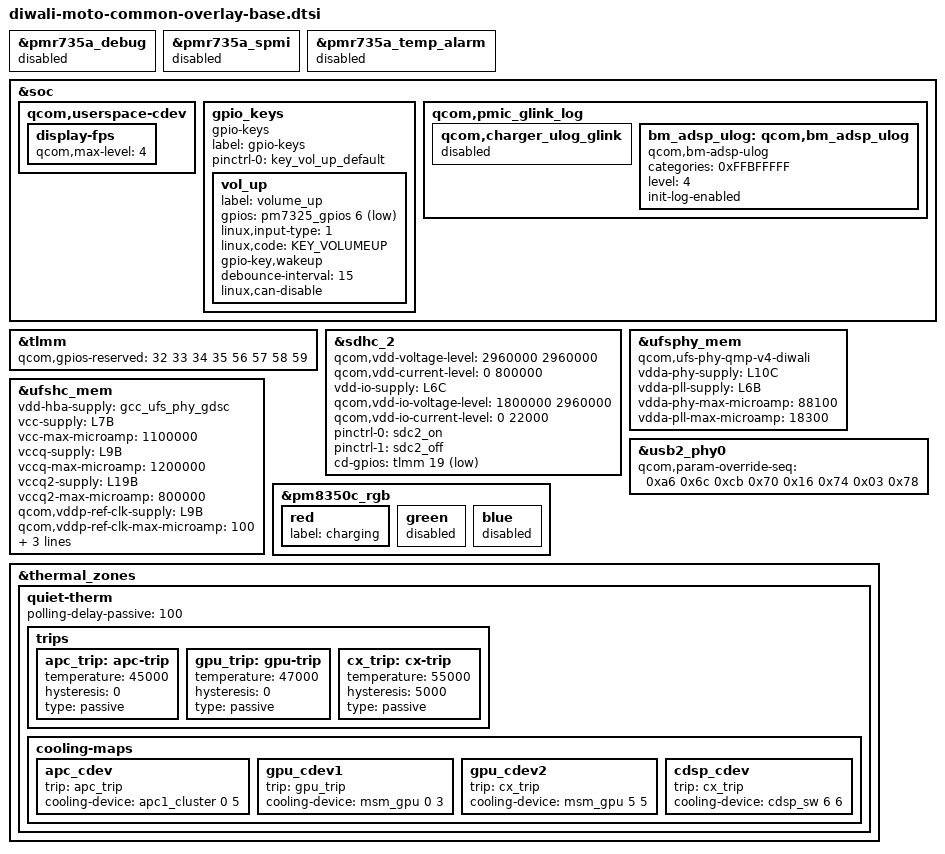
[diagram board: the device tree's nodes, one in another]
/* Copyright (c) 2022, The Linux Foundation. All rights reserved.
 *
 * This program is free software; you can redistribute it and/or modify
 * it under the terms of the GNU General Public License version 2 and
 * only version 2 as published by the Free Software Foundation.
 *
 * This program is distributed in the hope that it will be useful,
 * but WITHOUT ANY WARRANTY; without even the implied warranty of
 * MERCHANTABILITY or FITNESS FOR A PARTICULAR PURPOSE.  See the
 * GNU General Public License for more details.
 */

/*
   This base is original from "diwali-qrd.dtsi"
*/

#include <dt-bindings/gpio/gpio.h>
#include <dt-bindings/input/input.h>

#include "diwali-pmic-overlay.dtsi"
#include "diwali-thermal-overlay.dtsi"

&pmr735a_debug {
	status = "disabled";
};

&pmr735a_spmi {
	status = "disabled";
};

&pmr735a_temp_alarm {
	status = "disabled";
};

&soc {
	qcom,userspace-cdev {
		display-fps {
			qcom,max-level = <4>;
		};
	};

	gpio_keys {
		compatible = "gpio-keys";
		label = "gpio-keys";

		pinctrl-names = "default";
		pinctrl-0 = <&key_vol_up_default>;

		vol_up {
			label = "volume_up";
			gpios = <&pm7325_gpios 6 GPIO_ACTIVE_LOW>;
			linux,input-type = <1>;
			linux,code = <KEY_VOLUMEUP>;
			gpio-key,wakeup;
			debounce-interval = <15>;
			linux,can-disable;
		};

	};

	qcom,pmic_glink_log {
		qcom,charger_ulog_glink {
			status = "disabled";
		};
		bm_adsp_ulog: qcom,bm_adsp_ulog {
			compatible = "qcom,bm-adsp-ulog";
			categories = <0xFFBFFFFF>;
			level = <4>;
			init-log-enabled;
		};
	};
};

&tlmm {
	/* reserve FP GPIOs: gpio56,57,58,59 */
	qcom,gpios-reserved = <32 33 34 35 56 57 58 59>;
};

&sdhc_2 {
	status = "ok";
	//vdd-supply = <&L9C>;
	qcom,vdd-voltage-level = <2960000 2960000>;
	qcom,vdd-current-level = <0 800000>;

	vdd-io-supply = <&L6C>;
	qcom,vdd-io-voltage-level = <1800000 2960000>;
	qcom,vdd-io-current-level = <0 22000>;

	pinctrl-names = "default", "sleep";
	pinctrl-0 = <&sdc2_on>;
	pinctrl-1 = <&sdc2_off>;

	cd-gpios = <&tlmm 19 GPIO_ACTIVE_LOW>;
};

&ufsphy_mem {
	compatible = "qcom,ufs-phy-qmp-v4-diwali";

	vdda-phy-supply = <&L10C>;
	vdda-pll-supply = <&L6B>;
	vdda-phy-max-microamp = <88100>;
	vdda-pll-max-microamp = <18300>;

	status = "ok";
};

&ufshc_mem {
	vdd-hba-supply = <&gcc_ufs_phy_gdsc>;

	vcc-supply = <&L7B>;
	vcc-max-microamp = <1100000>;

	vccq-supply = <&L9B>;
	vccq-max-microamp = <1200000>;

	vccq2-supply = <&L19B>;
	vccq2-max-microamp = <800000>;

	qcom,vddp-ref-clk-supply = <&L9B>;
	qcom,vddp-ref-clk-max-microamp = <100>;

	/*
	 * ufs-dev-types and nvmem entries are for ufs device
	 * identification using nvmem interface. Use number of
	 * ufs devices supported for ufs-dev-types, and nvmem handle
	 * added by pmic for sdam register.
	 */
	ufs-dev-types = <2>;
	nvmem-cells = <&ufs_dev>;
	nvmem-cell-names = "ufs_dev";

	status = "ok";
};

&usb2_phy0 {
	qcom,param-override-seq = <
			/* override x0 */
			0xa6 0x6c
			/* override x1 */
			0xcb 0x70
			/* override x2 */
			0x16 0x74
			/* override x3 */
			0x03 0x78>;
};

&pm8350c_rgb {
	red {
		label = "charging";
	};

	green {
		status = "disabled";
	};

	blue {
		status = "disabled";
	};
};

&thermal_zones {
	quiet-therm {
		polling-delay-passive = <100>;

		trips {
			apc_trip:apc-trip {
				temperature = <45000>;
				hysteresis = <0>;
				type = "passive";
			};

			gpu_trip:gpu-trip {
				temperature = <47000>;
				hysteresis = <0>;
				type = "passive";
			};

			cx_trip:cx-trip {
				temperature = <55000>;
				hysteresis = <5000>;
				type = "passive";
			};
		};

		cooling-maps {
			apc_cdev {
				trip = <&apc_trip>;
				cooling-device = <&apc1_cluster 0 5>;
			};

			gpu_cdev1 {
				trip = <&gpu_trip>;
				/* Limit freq to 540000000 Hz*/
				cooling-device = <&msm_gpu 0 3>;
			};

			gpu_cdev2 {
				trip = <&cx_trip>;
				/* Limit freq to 285000000 Hz*/
				cooling-device = <&msm_gpu 5 5>;
			};

			cdsp_cdev {
				trip = <&cx_trip>;
				cooling-device = <&cdsp_sw 6 6>;
			};
		};
	};
};

